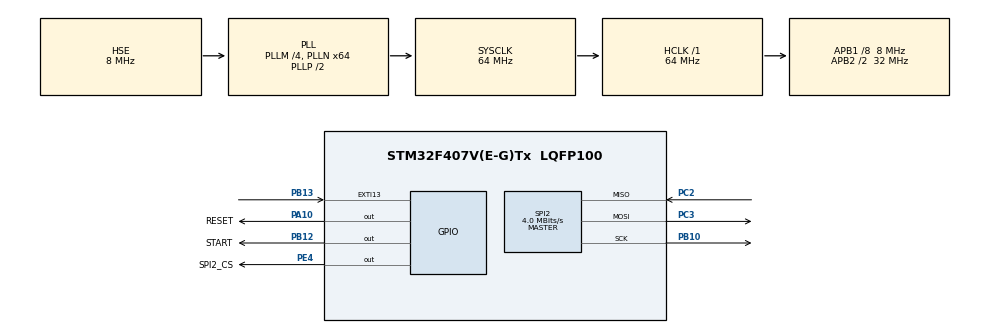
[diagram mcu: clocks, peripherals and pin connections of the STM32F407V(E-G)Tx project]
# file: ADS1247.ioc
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Mcu.Family=STM32F4
Mcu.Name=STM32F407V(E-G)Tx
Mcu.Package=LQFP100
NVIC.PriorityGroup=NVIC_PRIORITYGROUP_0
PA10.GPIO_Label=RESET
PA10.Signal=GPIO_Output
PB10.Mode=Full_Duplex_Master
PB10.Signal=SPI2_SCK
PB12.GPIO_Label=START
PB12.Signal=GPIO_Output
PB13.Signal=GPXTI13
PC2.Mode=Full_Duplex_Master
PC2.Signal=SPI2_MISO
PC3.Mode=Full_Duplex_Master
PC3.Signal=SPI2_MOSI
PE4.GPIO_Label=SPI2_CS
PE4.Signal=GPIO_Output
PH0-OSC_IN.Mode=HSE-External-Oscillator
PH0-OSC_IN.Signal=RCC_OSC_IN
PH1-OSC_OUT.Mode=HSE-External-Oscillator
PH1-OSC_OUT.Signal=RCC_OSC_OUT
ProjectManager.HeapSize=0x200
ProjectManager.StackSize=0x400
ProjectManager.TargetToolchain=STM32CubeIDE
RCC.48MHZClocksFreq_Value=18285714.285714287
RCC.AHBFreq_Value=64000000
RCC.APB1CLKDivider=RCC_HCLK_DIV8
RCC.APB1Freq_Value=8000000
RCC.APB1TimFreq_Value=16000000
RCC.APB2CLKDivider=RCC_HCLK_DIV2
RCC.APB2Freq_Value=32000000
RCC.APB2TimFreq_Value=64000000
RCC.CortexFreq_Value=64000000
RCC.HCLKFreq_Value=64000000
RCC.HSE_VALUE=8000000
RCC.HSI_VALUE=16000000
RCC.LSE_VALUE=32768
RCC.PLLM=4
RCC.PLLN=64
RCC.PLLQ=7
RCC.PLLSourceVirtual=RCC_PLLSOURCE_HSE
RCC.SYSCLKFreq_VALUE=64000000
RCC.SYSCLKSource=RCC_SYSCLKSOURCE_PLLCLK
RCC.VCOOutputFreq_Value=128000000
SPI2.CLKPhase=SPI_PHASE_2EDGE
SPI2.CalculateBaudRate=4.0 MBits/s
SPI2.Direction=SPI_DIRECTION_2LINES
SPI2.Mode=SPI_MODE_MASTER
SPI2.VirtualType=VM_MASTER
board=STM32F407G-DISC1

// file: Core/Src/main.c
/* USER CODE BEGIN Header */
/**
  ******************************************************************************
  * @file           : main.c
  * @brief          : Main program body
  ******************************************************************************
  * @attention
  *
  * Copyright (c) 2025 STMicroelectronics.
  * All rights reserved.
  *
  * This software is licensed under terms that can be found in the LICENSE file
  * in the root directory of this software component.
  * If no LICENSE file comes with this software, it is provided AS-IS.
  *
  ******************************************************************************
  */
/* USER CODE END Header */
#include "main.h"
#include "spi.h"
#include "gpio.h"
#include "math.h"
#include "ADS1247.h"

uint8_t status;
int32_t raw;
double voltage;
double result_temp=0;
/* USER CODE END PV */

void SystemClock_Config(void);
double calculate_RTD(int32_t adc_code, double Rref, int gain)
{
	const int32_t ADC_FULLSCALE =8388608;  // 2^23
    return (Rref * adc_code) / (ADC_FULLSCALE * gain);
}
void test_RTD(){
	static double R0 =  100;//0 degree for 100 ohm
	static double A =  0.00390802;//by IEC-60751
	static double B = -0.0000005802;
	adc124xx_t ads={
			.sel_channel_P=P_AIN1,
			.sel_channel_N=N_AIN2,
			.sel_bias=DIS_BIAS_AINx,
			.sel_dr=DOR3_20,
			.sel_exc_mag=IMAG2_1000,
			.sel_exc_out=I2DIR_AIN0|I2DIR_AIN3,
			.sel_internal_ref=VREFCON1_ON,
			.sel_ref=REFSELT1_ON,
			.sel_pga=PGA2_0,
			.sel_sys_moniter=MUXCAL2_NORMAL
	};
	rtd_init(&ads);
	raw =  ADS1247_ReadData();
	double result_volt=ads1247_raw_to_voltage(raw, 2.048, 1);
//	double result_resistance = result_volt/0.002; //
	double result_resistance=calculate_RTD(raw,1000,32);
	result_temp = (-R0*A+sqrt(pow(R0*A,2)-4*R0*B*(R0-result_resistance)))/(2*R0*B);
	//Define PT100 Coeffients

}

/* USER CODE END 0 */

void analog_supplie_init(){
	  // Reset and Start
	  RESET_LOW;
	  HAL_Delay(10);
	  RESET_HIGH;
	  HAL_Delay(10);

	  START_HIGH;
	  HAL_Delay(10);

	  // Stop continuous read
	  uint8_t cmd = CMD_SDATAC;
	  CS_LOW;
	  HAL_Delay(10);
	  HAL_SPI_Transmit(&hspi2, &cmd, 1, 2000);
	  HAL_Delay(10);
	  CS_HIGH;
	  HAL_Delay(1000);

	  // Configure basic registers

//	  ADS1247_write_register(REG_MUX0,1, P_AIN0|N_AINCOM);
//	  HAL_Delay(10);
//	  uint8_t var=ADS1247_read_register(REG_MUX0,1);//optional for sanity check
//	  HAL_Delay(10);
//
//	  ADS1247_write_register(REG_MUX1,1,VREFCON1_ON | REFSELT1_ON);
//	  HAL_Delay(10);
//	  var=ADS1247_read_register(REG_MUX1,1);////optional for sanity check
//	  HAL_Delay(10);

//	  ADS1247_write_register(REG_SYS0,1,PGA2_0 | DOR3_5);
//	  uint8_t var=ADS1247_read_register(REG_SYS0,1);////optional for sanity check
//	  HAL_Delay(10);
	  //ADS1247_write_register(REG_VBIAS,1,EN_BIAS_AIN0 | EN_BIAS_AIN1);

	adc124xx_t ads={
			.sel_channel_P=P_AIN0,
			.sel_channel_N=N_AIN1,
			.sel_bias=DIS_BIAS_AINx,
			.sel_dr=DOR3_5,
			.sel_exc_mag=IMAG2_OFF,
			.sel_exc_out=I1DIR_OFF|I2DIR_OFF,
			.sel_internal_ref=VREFCON1_ON,
			.sel_ref=REFSELT1_ON,
			.sel_pga=PGA2_0,
			.sel_sys_moniter=MUXCAL2_AVDD
	};
	ads1247_init(&ads);
}
int main(void)
{

  /* USER CODE BEGIN 1 */
//	char *data="UART2 TESTING\n\r";

  /* USER CODE END 1 */
	HAL_Delay(2000); // Add a 2-second delay
	HAL_FLASH_Unlock();
	// Flash operations here
	HAL_FLASH_Lock();
  /* MCU Configuration--------------------------------------------------------*/

  /* Reset of all peripherals, Initializes the Flash interface and the Systick. */

	HAL_Init();

  /* USER CODE BEGIN Init */
 // uint8_t temp[2];
  /* USER CODE END Init */

  /* Configure the system clock */
  SystemClock_Config();

  /* Initialize all configured peripherals */
  MX_GPIO_Init();
  MX_SPI2_Init();
  ADS1247_begin();
  analog_supplie_init();

  while (1)
  {
	 status=HAL_GPIO_ReadPin(DRDY_PORT, DRDY_PIN);
    if (HAL_GPIO_ReadPin(DRDY_PORT, DRDY_PIN) == GPIO_PIN_RESET)
    {
//    	raw =  ADS1247_ReadData();
//    	voltage = (2.048 / 16777216)*raw;

      raw = ADS1247_ReadData();
     // result_temp =ads1247_raw_to_voltage(raw, 2.048,1);
      result_temp =ads1247_raw_to_voltage(raw, 2.96,1);

//      HAL_Delay(1000);

    }
  }
  /* USER CODE END 3 */
}

void SystemClock_Config(void)
{
  RCC_OscInitTypeDef RCC_OscInitStruct = {0};
  RCC_ClkInitTypeDef RCC_ClkInitStruct = {0};

  /** Configure the main internal regulator output voltage
  */
  __HAL_RCC_PWR_CLK_ENABLE();
  __HAL_PWR_VOLTAGESCALING_CONFIG(PWR_REGULATOR_VOLTAGE_SCALE1);

  /** Initializes the RCC Oscillators according to the specified parameters
  * in the RCC_OscInitTypeDef structure.
  */
  RCC_OscInitStruct.OscillatorType = RCC_OSCILLATORTYPE_HSE;
  RCC_OscInitStruct.HSEState = RCC_HSE_ON;
  RCC_OscInitStruct.PLL.PLLState = RCC_PLL_ON;
  RCC_OscInitStruct.PLL.PLLSource = RCC_PLLSOURCE_HSE;
  RCC_OscInitStruct.PLL.PLLM = 4;
  RCC_OscInitStruct.PLL.PLLN = 64;
  RCC_OscInitStruct.PLL.PLLP = RCC_PLLP_DIV2;
  RCC_OscInitStruct.PLL.PLLQ = 7;
  if (HAL_RCC_OscConfig(&RCC_OscInitStruct) != HAL_OK)
  {
    Error_Handler();
  }

  /** Initializes the CPU, AHB and APB buses clocks
  */
  RCC_ClkInitStruct.ClockType = RCC_CLOCKTYPE_HCLK|RCC_CLOCKTYPE_SYSCLK
                              |RCC_CLOCKTYPE_PCLK1|RCC_CLOCKTYPE_PCLK2;
  RCC_ClkInitStruct.SYSCLKSource = RCC_SYSCLKSOURCE_PLLCLK;
  RCC_ClkInitStruct.AHBCLKDivider = RCC_SYSCLK_DIV1;
  RCC_ClkInitStruct.APB1CLKDivider = RCC_HCLK_DIV8;
  RCC_ClkInitStruct.APB2CLKDivider = RCC_HCLK_DIV2;

  if (HAL_RCC_ClockConfig(&RCC_ClkInitStruct, FLASH_LATENCY_2) != HAL_OK)
  {
    Error_Handler();
  }
}

void Error_Handler(void)
{
  __disable_irq();
  while (1)
  {
  }
}
